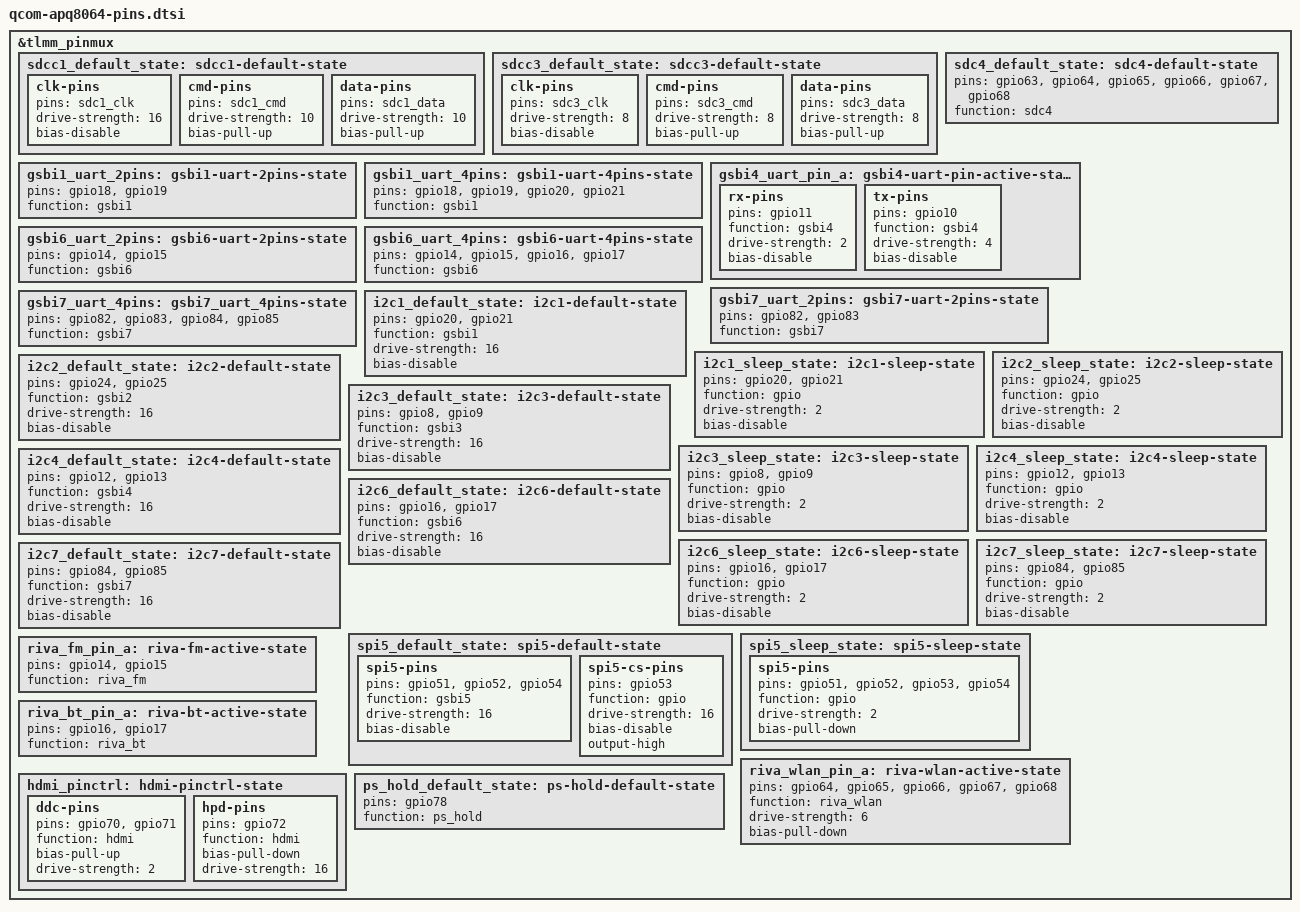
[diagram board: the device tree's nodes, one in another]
// SPDX-License-Identifier: GPL-2.0

&tlmm_pinmux {
	sdcc1_default_state: sdcc1-default-state {
		clk-pins {
			pins = "sdc1_clk";
			drive-strength = <16>;
			bias-disable;
		};

		cmd-pins {
			pins = "sdc1_cmd";
			drive-strength = <10>;
			bias-pull-up;
		};

		data-pins {
			pins = "sdc1_data";
			drive-strength = <10>;
			bias-pull-up;
		};
	};

	sdcc3_default_state: sdcc3-default-state {
		clk-pins {
			pins = "sdc3_clk";
			drive-strength = <8>;
			bias-disable;
		};

		cmd-pins {
			pins = "sdc3_cmd";
			drive-strength = <8>;
			bias-pull-up;
		};

		data-pins {
			pins = "sdc3_data";
			drive-strength = <8>;
			bias-pull-up;
		};
	};

	sdc4_default_state: sdc4-default-state {
		pins = "gpio63", "gpio64", "gpio65", "gpio66", "gpio67", "gpio68";
		function = "sdc4";
	};

	gsbi1_uart_2pins: gsbi1-uart-2pins-state {
		pins = "gpio18", "gpio19";
		function = "gsbi1";
	};

	gsbi1_uart_4pins: gsbi1-uart-4pins-state {
		pins = "gpio18", "gpio19", "gpio20", "gpio21";
		function = "gsbi1";
	};

	gsbi4_uart_pin_a: gsbi4-uart-pin-active-state {
		rx-pins {
			pins = "gpio11";
			function = "gsbi4";
			drive-strength = <2>;
			bias-disable;
		};

		tx-pins {
			pins = "gpio10";
			function = "gsbi4";
			drive-strength = <4>;
			bias-disable;
		};
	};

	gsbi6_uart_2pins: gsbi6-uart-2pins-state {
		pins = "gpio14", "gpio15";
		function = "gsbi6";
	};

	gsbi6_uart_4pins: gsbi6-uart-4pins-state {
		pins = "gpio14", "gpio15", "gpio16", "gpio17";
		function = "gsbi6";
	};

	gsbi7_uart_2pins: gsbi7-uart-2pins-state {
		pins = "gpio82", "gpio83";
		function = "gsbi7";
	};

	gsbi7_uart_4pins: gsbi7_uart_4pins-state {
		pins = "gpio82", "gpio83", "gpio84", "gpio85";
		function = "gsbi7";
	};

	i2c1_default_state: i2c1-default-state {
		pins = "gpio20", "gpio21";
		function = "gsbi1";
		drive-strength = <16>;
		bias-disable;
	};

	i2c1_sleep_state: i2c1-sleep-state {
		pins = "gpio20", "gpio21";
		function = "gpio";
		drive-strength = <2>;
		bias-disable;
	};

	i2c2_default_state: i2c2-default-state {
		pins = "gpio24", "gpio25";
		function = "gsbi2";
		drive-strength = <16>;
		bias-disable;
	};

	i2c2_sleep_state: i2c2-sleep-state {
		pins = "gpio24", "gpio25";
		function = "gpio";
		drive-strength = <2>;
		bias-disable;
	};

	i2c3_default_state: i2c3-default-state {
		pins = "gpio8", "gpio9";
		function = "gsbi3";
		drive-strength = <16>;
		bias-disable;
	};

	i2c3_sleep_state: i2c3-sleep-state {
		pins = "gpio8", "gpio9";
		function = "gpio";
		drive-strength = <2>;
		bias-disable;
	};

	i2c4_default_state: i2c4-default-state {
		pins = "gpio12", "gpio13";
		function = "gsbi4";
		drive-strength = <16>;
		bias-disable;
	};

	i2c4_sleep_state: i2c4-sleep-state {
		pins = "gpio12", "gpio13";
		function = "gpio";
		drive-strength = <2>;
		bias-disable;
	};

	i2c6_default_state: i2c6-default-state {
		pins = "gpio16", "gpio17";
		function = "gsbi6";
		drive-strength = <16>;
		bias-disable;
	};

	i2c6_sleep_state: i2c6-sleep-state {
		pins = "gpio16", "gpio17";
		function = "gpio";
		drive-strength = <2>;
		bias-disable;
	};

	i2c7_default_state: i2c7-default-state {
		pins = "gpio84", "gpio85";
		function = "gsbi7";
		drive-strength = <16>;
		bias-disable;
	};

	i2c7_sleep_state: i2c7-sleep-state {
		pins = "gpio84", "gpio85";
		function = "gpio";
		drive-strength = <2>;
		bias-disable;
	};

	spi5_default_state: spi5-default-state {
		spi5-pins {
			pins = "gpio51", "gpio52", "gpio54";
			function = "gsbi5";
			drive-strength = <16>;
			bias-disable;
		};

		spi5-cs-pins {
			pins = "gpio53";
			function = "gpio";
			drive-strength = <16>;
			bias-disable;
			output-high;
		};
	};

	spi5_sleep_state: spi5-sleep-state {
		spi5-pins {
			pins = "gpio51", "gpio52", "gpio53", "gpio54";
			function = "gpio";
			drive-strength = <2>;
			bias-pull-down;
		};
	};

	riva_fm_pin_a: riva-fm-active-state {
		pins = "gpio14", "gpio15";
		function = "riva_fm";
	};

	riva_bt_pin_a: riva-bt-active-state {
		pins = "gpio16", "gpio17";
		function = "riva_bt";
	};

	riva_wlan_pin_a: riva-wlan-active-state {
		pins = "gpio64", "gpio65", "gpio66", "gpio67", "gpio68";
		function = "riva_wlan";

		drive-strength = <6>;
		bias-pull-down;
	};

	hdmi_pinctrl: hdmi-pinctrl-state {
		ddc-pins {
			pins = "gpio70", "gpio71";
			function = "hdmi";
			bias-pull-up;
			drive-strength = <2>;
		};

		hpd-pins {
			pins = "gpio72";
			function = "hdmi";
			bias-pull-down;
			drive-strength = <16>;
		};
	};

	ps_hold_default_state: ps-hold-default-state {
		pins = "gpio78";
		function = "ps_hold";
	};
};
